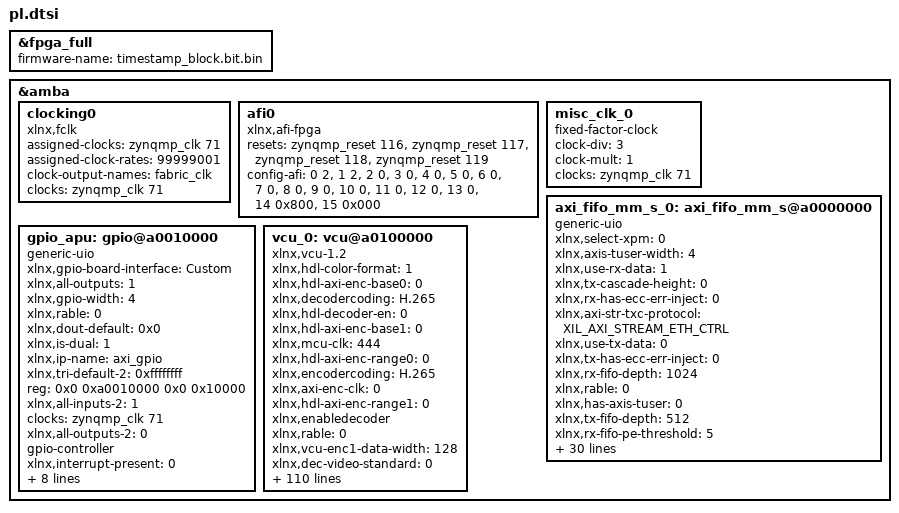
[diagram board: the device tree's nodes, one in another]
/dts-v1/;
/plugin/;

&fpga_full {
	#address-cells = <2>;
	#size-cells = <2>;
	firmware-name = "timestamp_block.bit.bin";
};

&amba {
	#address-cells = <2>;
	#size-cells = <2>;
	clocking0: clocking0 {
		compatible = "xlnx,fclk";
		status = "okay";
		assigned-clocks = <&zynqmp_clk 71>;
		assigned-clock-rates = <99999001>;
		#clock-cells = <0>;
		clock-output-names = "fabric_clk";
		clocks = <&zynqmp_clk 71>;
	};
	afi0: afi0 {
		status = "okay";
		compatible = "xlnx,afi-fpga";
		resets = <&zynqmp_reset 116>, <&zynqmp_reset 117>, <&zynqmp_reset 118>, <&zynqmp_reset 119>;
		config-afi = < 0 2>, <1 2>, <2 0>, <3 0>, <4 0>, <5 0>, <6 0>, <7 0>, <8 0>, <9 0>, <10 0>, <11 0>, <12 0>, <13 0>, <14 0x800>, <15 0x000>;
	};
	misc_clk_0: misc_clk_0 {
		clock-div = <3>;
		compatible = "fixed-factor-clock";
		clock-mult = <1>;
		clocks = <&zynqmp_clk 71>;
		#clock-cells = <0>;
	};
	axi_fifo_mm_s_0: axi_fifo_mm_s@a0000000 {
		xlnx,select-xpm = <0>;
		xlnx,axis-tuser-width = <4>;
		compatible = "generic-uio";
		xlnx,use-rx-data = <1>;
		xlnx,tx-cascade-height = <0>;
		xlnx,rx-has-ecc-err-inject = <0>;
		xlnx,axi-str-txc-protocol = "XIL_AXI_STREAM_ETH_CTRL";
		xlnx,use-tx-data = <0>;
		xlnx,tx-has-ecc-err-inject = <0>;
		xlnx,rx-fifo-depth = <1024>;
		xlnx,rable = <0>;
		xlnx,has-axis-tuser = <0>;
		xlnx,tx-fifo-depth = <512>;
		xlnx,rx-fifo-pe-threshold = <5>;
		xlnx,data-interface-type = <0>;
		xlnx,ip-name = "axi_fifo_mm_s";
		xlnx,use-tx-ctrl = <0>;
		xlnx,rx-fifo-pf-threshold = <507>;
		xlnx,axis-tid-width = <4>;
		reg = <0x0 0xa0000000 0x0 0x10000>;
		clocks = <&zynqmp_clk 71>;
		xlnx,tx-fifo-pe-threshold = <5>;
		xlnx,tx-fifo-pf-threshold = <507>;
		xlnx,s-axi4-data-width = <32>;
		xlnx,has-axis-tstrb = <0>;
		xlnx,axi-str-rxd-protocol = "XIL_AXI_STREAM_ETH_DATA";
		xlnx,use-rx-cut-through = <0>;
		xlnx,axi-str-rxd-tdata-width = <32>;
		xlnx,axis-tdest-width = <4>;
		xlnx,edk-iptype = "PERIPHERAL";
		xlnx,has-axis-tkeep = <0>;
		xlnx,has-axis-tid = <0>;
		xlnx,axi-str-txc-tdata-width = <32>;
		xlnx,axi-str-txd-protocol = "XIL_AXI_STREAM_ETH_DATA";
		xlnx,use-tx-cut-through = <0>;
		xlnx,axi-str-txd-tdata-width = <32>;
		xlnx,rx-enable-ecc = <0>;
		status = "okay";
		clock-names = "s_axi_aclk";
		xlnx,has-axis-tdest = <0>;
		xlnx,tx-enable-ecc = <0>;
		xlnx,s-axi-id-width = <4>;
		xlnx,rx-cascade-height = <0>;
		xlnx,name = "axi_fifo_mm_s_0";
	};
	gpio_apu: gpio@a0010000 {
		xlnx,gpio-board-interface = "Custom";
		compatible = "generic-uio";
		xlnx,all-outputs = <1>;
		#gpio-cells = <2>;
		xlnx,gpio-width = <4>;
		xlnx,rable = <0>;
		xlnx,dout-default = <0x0>;
		xlnx,is-dual = <1>;
		xlnx,ip-name = "axi_gpio";
		xlnx,tri-default-2 = <0xffffffff>;
		reg = <0x0 0xa0010000 0x0 0x10000>;
		xlnx,all-inputs-2 = <1>;
		clocks = <&zynqmp_clk 71>;
		xlnx,all-outputs-2 = <0>;
		gpio-controller;
		xlnx,interrupt-present = <0>;
		xlnx,gpio2-board-interface = "Custom";
		xlnx,edk-iptype = "PERIPHERAL";
		xlnx,dout-default-2 = <0x0>;
		status = "okay";
		xlnx,gpio2-width = <32>;
		clock-names = "s_axi_aclk";
		xlnx,use-board-flow;
		xlnx,tri-default = <0xffffffff>;
		xlnx,name = "gpio_apu";
		xlnx,all-inputs = <0>;
	};
	vcu_0: vcu@a0100000 {
		xlnx,hdl-color-format = <1>;
		xlnx,hdl-axi-enc-base0 = <0>;
		xlnx,decodercoding = "H.265";
		xlnx,hdl-decoder-en = <0>;
		xlnx,hdl-axi-enc-base1 = <0>;
		xlnx,mcu-clk = <444>;
		xlnx,hdl-axi-enc-range0 = <0>;
		xlnx,encodercoding = "H.265";
		xlnx,axi-enc-clk = <0>;
		xlnx,hdl-axi-enc-range1 = <0>;
		xlnx,enabledecoder;
		xlnx,rable = <0>;
		xlnx,vcu-enc1-data-width = <128>;
		xlnx,dec-video-standard = <0>;
		xlnx,pll-bypass = <0>;
		xlnx,hdl-dec-fps = <60>;
		xlnx,encverresolution = <2160>;
		xlnx,enc-mem-bram-used = <0>;
		xlnx,ip-name = "vcu";
		#size-cells = <2>;
		reg = <0x0 0xa0140000 0x0 0x1000>, <0x0 0xa0141000 0x0 0x1000>;
		xlnx,hdl-enc-clk = <0>;
		xlnx,hdl-enc-buffer-en = <0>;
		#address-cells = <2>;
		xlnx,hdl-axi-mcu-range = <0>;
		xlnx,vcu-dec0-data-width = <128>;
		xlnx,enc-fps = <3>;
		xlnx,dec-coding-type = <0>;
		xlnx,axi-enc-range0 = <0>;
		interrupt-names = "vcu_host_interrupt";
		xlnx,hdl-vcu-test-en = <0>;
		xlnx,hdl-coding-type = <0>;
		xlnx,enc-color-format = <1>;
		xlnx,axi-enc-range1 = <0>;
		xlnx,decoderchromaformat = "4_2_2";
		compatible = "xlnx,vcu-1.2" , "xlnx,vcu";
		xlnx,vcu-axiliteapb-data-width = <32>;
		xlnx,dec-color-depth = <1>;
		xlnx,hdl-encoder-en = <0>;
		xlnx,decverresolution = <2160>;
		interrupt-parent = <&gic>;
		xlnx,hdl-dec-frame-size-x = <3840>;
		xlnx,hdl-color-depth = <1>;
		xlnx,hdl-dec-frame-size-y = <2160>;
		xlnx,hdl-axi-mcu-clk = <333>;
		xlnx,enc-video-standard = <0>;
		ranges;
		xlnx,enc-mem-uram-used = <0>;
		xlnx,decodernumcores = <2>;
		xlnx,no-of-streams = <1>;
		xlnx,hdl-dec-video-standard = <0>;
		xlnx,axi-mcu-clk = <333>;
		xlnx,hdl-pll-bypass = <0>;
		xlnx,enc-buffer-manual-override = <0>;
		status = "okay";
		xlnx,dec-color-format = <1>;
		xlnx,pll-clk = <0x1f7950c>;
		xlnx,hdl-test-port-en = <0>;
		xlnx,hdl-axi-dec-clk = <0>;
		xlnx,hdl-mcu-clk = <444>;
		xlnx,hdl-axi-mcu-base = <0>;
		xlnx,name = "vcu_0";
		interrupts = < 0 89 4 >;
		xlnx,table-no = <0>;
		xlnx,axi-dec-clk = <0>;
		xlnx,hdl-dec-color-format = <1>;
		xlnx,hdl-ram-type = <0>;
		xlnx,hdl-pll-clk-lo = <0>;
		xlnx,vcu-dec1-data-width = <128>;
		xlnx,vcu-mcu-data-width = <32>;
		xlnx,dec-frame-size = <4>;
		xlnx,enc-buffer-size-actual = <0>;
		xlnx,enc-buffer-size = <0>;
		xlnx,hdl-table-no = <0>;
		xlnx,enableencoder;
		clocks = <&misc_clk_0>, <&zynqmp_clk 71>, <&vcu_0 0>, <&vcu_0 1>, <&vcu_0 2>, <&vcu_0 3>;
		xlnx,hdl-dec-coding-type = <0>;
		xlnx,hdl-video-standard = <0>;
		xlnx,dec-fps = <3>;
		xlnx,edk-iptype = "PERIPHERAL";
		xlnx,enc-buffer-b-frame = <0>;
		xlnx,enc-clk = <0>;
		xlnx,vcu-enc0-data-width = <128>;
		xlnx,hdl-fps = <60>;
		xlnx,enc-coding-type = <0>;
		clock-names = "pll_ref" , "aclk" , "vcu_core_enc" , "vcu_mcu_enc" , "vcu_core_dec" , "vcu_mcu_dec";
		xlnx,hdl-dec-color-depth = <1>;
		xlnx,hdl-enc-buffer-motion-vec-range = <0>;
		xlnx,hdl-enc-buffer-manual-override = <0>;
		xlnx,hdl-axi-dec-range0 = <0>;
		xlnx,hdl-axi-dec-range1 = <0>;
		xlnx,encoderchromaformat = "4_2_2";
		xlnx,enchorresolution = <3840>;
		xlnx,axi-dec-base0 = <0>;
		xlnx,no-of-dec-streams = <1>;
		xlnx,hdl-wpp-en = <0>;
		xlnx,enc-color-depth = <1>;
		xlnx,axi-dec-base1 = <0>;
		xlnx,decodercodingtype = "INTRA_ONLY";
		xlnx,enc-buffer-type = <0>;
		xlnx,hdl-frame-size-x = <3840>;
		xlnx,axi-enc-base0 = <0>;
		xlnx,enc-buffer-motion-vec-range = <0>;
		xlnx,hdl-frame-size-y = <2160>;
		xlnx,encodercodingtype = "INTRA_ONLY";
		xlnx,enc-frame-size = <4>;
		xlnx,axi-enc-base1 = <0>;
		xlnx,core-clk = <667>;
		xlnx,hdl-num-concurrent-streams = <1>;
		xlnx,hdl-pll-clk-hi = <33>;
		xlnx,decodercolordepth = <10>;
		xlnx,encodernumcores = <4>;
		xlnx,encodercolordepth = <10>;
		xlnx,axi-mcu-base = <0>;
		xlnx,hdl-core-clk = <667>;
		xlnx,axi-dec-range0 = <0>;
		xlnx,hdl-mem-depth = <0>;
		xlnx,axi-dec-range1 = <0>;
		xlnx,axi-mcu-range = <0>;
		xlnx,wpp-en = <0>;
		xlnx,hdl-axi-dec-base0 = <0>;
		reg-names = "vcu_slcr" , "logicore";
		#clock-cells = <1>;
		xlnx,mcu-debug = <0>;
		xlnx,hdl-num-streams = <1>;
		xlnx,hdl-max-num-cores = <4>;
		xlnx,hdl-enc-buffer-b-frame = <0>;
		xlnx,hdl-axi-enc-clk = <0>;
		xlnx,hdl-axi-dec-base1 = <0>;
		xlnx,coreclkfreq = <667>;
		xlnx,dechorresolution = <3840>;
	};
};
